# STM32L4S5 register map
File version: 2.0
CPU: CM4 r0p1, little endian, MPU, FPU, 4 interrupt priority bits
Registers are 32-bit, read-write, reset 0x0 unless marked. A register's access mark holds for its fields unless they carry their own. Offsets are from the block's base; [hi:lo] are bit positions; {n}, {i} and the like mark numbered series; 'fields as' and 'values as' point back to an identical list.

## GFXMMU — Graphic MMU
Base 0x4002C000
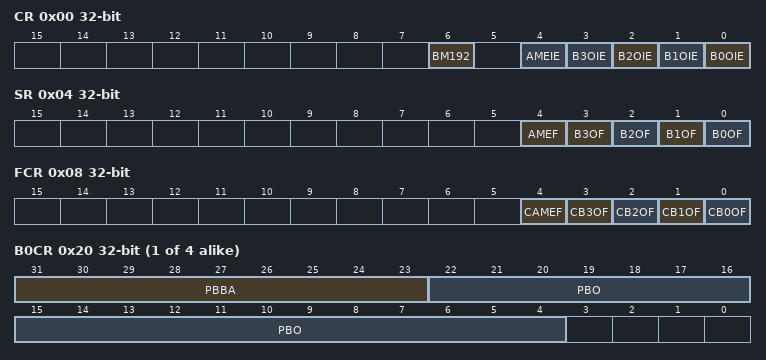
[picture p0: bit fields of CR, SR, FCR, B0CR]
0x00 CR — Graphic MMU configuration register
  [6] BM192 — 192 Block mode
  [4] AMEIE — AHB master error interrupt enable
  [n] B{n}OIE (n=0..3) — Buffer {n} overflow interrupt enable
0x04 SR ro — Graphic MMU status register
  [4] AMEF — AHB master error flag
  [n] B{n}OF (n=0..3) — Buffer {n} overflow flag
0x08 FCR wo — Graphic MMU flag clear register
  [4] CAMEF — Clear AHB master error flag
  [n] CB{n}OF (n=0..3) — Clear buffer {n} overflow flag
0x10 DVR — Graphic MMU default value register
  [31:0] DV — Default value
{0x20+4i} B{i}CR (i=0..3) — Graphic MMU buffer {i} configuration register
  [31:23] PBBA — Physical buffer base address
  [22:4] PBO — Physical buffer offset
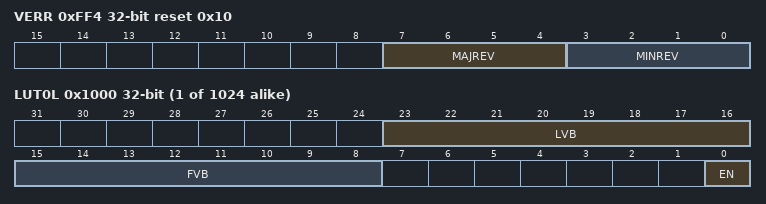
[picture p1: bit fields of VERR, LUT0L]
0xFF4 VERR ro reset 0x10 — Graphic MMU version register
  [7:4] MAJREV — Major revision
  [3:0] MINREV — Minor revision
0xFF8 IPIDR ro reset 0x160061 — Graphic MMU identification register
  [31:0] ID — Identification Code
0xFFC SIDR ro reset 0xA3C5DD04 — Graphic MMU size identification register
  [31:0] SID — Size and ID
{0x1000+8i} LUT{i}L (i=0..1023) — Graphic MMU LUT entry {i} low
  [23:16] LVB — Last Valid Block
  [15:8] FVB — First Valid Block
  [0] EN — Enable
{0x1004+8i} LUT{i}H (i=0..1023) — Graphic MMU LUT entry {i} high
  [21:4] LO — Line offset

## OCTOSPIM — OctoSPI IO Manager
Base 0x50061C00
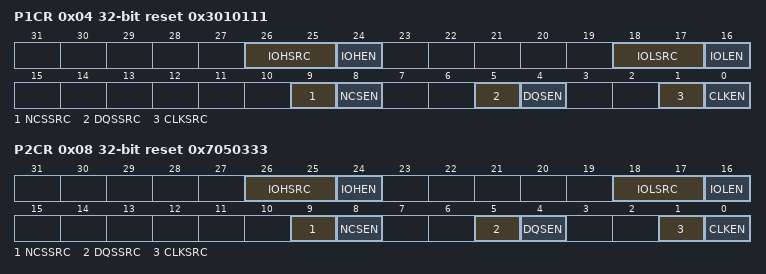
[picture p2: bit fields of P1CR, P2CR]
0x04 P1CR reset 0x3010111 — OctoSPI IO Manager Port 1 Configuration Register
  [26:25] IOHSRC — Source for Port
  [24] IOHEN — Enable for Port n
  [18:17] IOLSRC — Source for Port
  [16] IOLEN — Enable for Port
  [9] NCSSRC — CS Source for Port
  [8] NCSEN — CS Enable for Port
  [5] DQSSRC — DQS Source for Port
  [4] DQSEN — DQS Enable for Port
  [1] CLKSRC — CLK/CLK Source for Port
  [0] CLKEN — CLK/CLK Enable for Port
0x08 P2CR reset 0x7050333 — OctoSPI IO Manager Port 2 Configuration Register
  fields as P1CR

## FPU — Floting point unit
Base 0xE000EF34
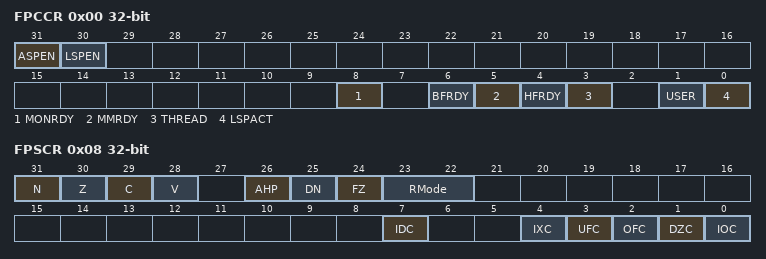
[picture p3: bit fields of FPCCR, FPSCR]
0x00 FPCCR — Floating-point context control register
  [31] ASPEN, [30] LSPEN, [8] MONRDY, [6] BFRDY, [5] MMRDY, [4] HFRDY, [3] THREAD, [1] USER, [0] LSPACT
0x04 FPCAR — Floating-point context address register
  [31:3] ADDRESS — Location of unpopulated floating-point
0x08 FPSCR — Floating-point status control register
  [31] N — Negative condition code flag
  [30] Z — Zero condition code flag
  [29] C — Carry condition code flag
  [28] V — Overflow condition code flag
  [26] AHP — Alternative half-precision control bit
  [25] DN — Default NaN mode control bit
  [24] FZ — Flush-to-zero mode control bit:
  [23:22] RMode — Rounding Mode control field
  [7] IDC — Input denormal cumulative exception bit.
  [4] IXC — Inexact cumulative exception bit
  [3] UFC — Underflow cumulative exception bit
  [2] OFC — Overflow cumulative exception bit
  [1] DZC — Division by zero cumulative exception bit.
  [0] IOC — Invalid operation cumulative exception bit

## MPU — Memory protection unit
Base 0xE000ED90
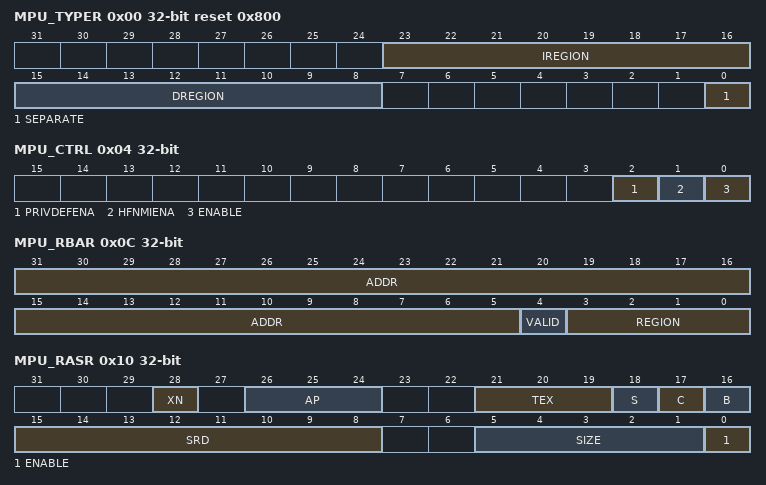
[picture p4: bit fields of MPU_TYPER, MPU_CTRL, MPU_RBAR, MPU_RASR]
0x00 MPU_TYPER ro reset 0x800 — MPU type register
  [23:16] IREGION — Number of MPU instruction regions
  [15:8] DREGION — Number of MPU data regions
  [0] SEPARATE — Separate flag
0x04 MPU_CTRL — MPU control register
  [2] PRIVDEFENA — Enable priviliged software access to default memory map
  [1] HFNMIENA — Enables the operation of MPU during hard fault
  [0] ENABLE — Enables the MPU
0x08 MPU_RNR — MPU region number register
  [7:0] REGION — MPU region
0x0C MPU_RBAR — MPU region base address register
  [31:5] ADDR — Region base address field
  [4] VALID — MPU region number valid
  [3:0] REGION — MPU region field
0x10 MPU_RASR — MPU region attribute and size register
  [28] XN — Instruction access disable bit
  [26:24] AP — Access permission
  [21:19] TEX — memory attribute
  [18] S — Shareable memory attribute
  [17] C — memory attribute
  [16] B — memory attribute
  [15:8] SRD — Subregion disable bits
  [5:1] SIZE — Size of the MPU protection region
  [0] ENABLE — Region enable bit.

## STK — SysTick timer
Base 0xE000E010
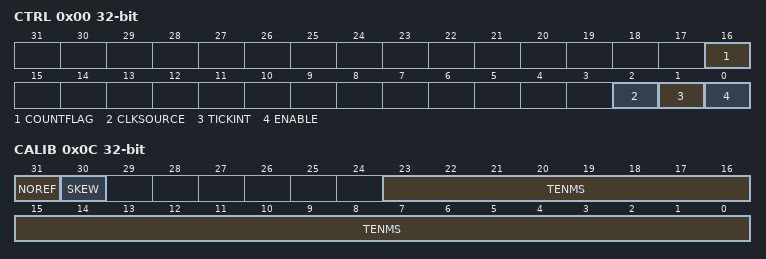
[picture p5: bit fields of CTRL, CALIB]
0x00 CTRL — SysTick control and status register
  [16] COUNTFLAG
  [2] CLKSOURCE — Clock source selection
  [1] TICKINT — SysTick exception request enable
  [0] ENABLE — Counter enable
0x04 LOAD — SysTick reload value register
  [23:0] RELOAD — RELOAD value
0x08 VAL — SysTick current value register
  [23:0] CURRENT — Current counter value
0x0C CALIB — SysTick calibration value register
  [31] NOREF — NOREF flag. Reads as zero
  [30] SKEW — SKEW flag: Indicates whether the TENMS value is exact
  [23:0] TENMS — Calibration value

## NVIC_STIR — Nested vectored interrupt controller
Base 0xE000EF00
0x00 STIR — Software trigger interrupt register
  [8:0] INTID — Software generated interrupt ID

## FPU_CPACR — Floating point unit CPACR
Base 0xE000ED88
0x00 CPACR — Coprocessor access control register
  [23:20] CP

## SCB_ACTRL — System control block ACTLR
Base 0xE000E008
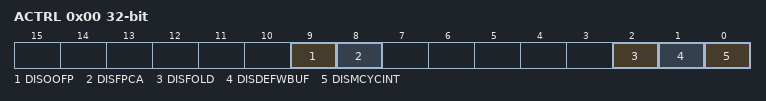
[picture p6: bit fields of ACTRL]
0x00 ACTRL — Auxiliary control register
  [9] DISOOFP, [8] DISFPCA, [2] DISFOLD, [1] DISDEFWBUF, [0] DISMCYCINT
